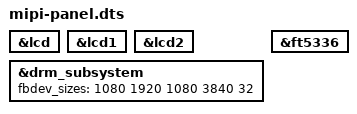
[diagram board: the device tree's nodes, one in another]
/dts-v1/;
/plugin/;

/ {
	fragment@0 {
		target = <&lcd>;

		__overlay__ {
			status = "okay";
		};
	};

	fragment@1 {
		target = <&lcd1>;

		__overlay__ {
			status = "okay";
		};
	};

	fragment@2 {
		target = <&lcd2>;

		__overlay__ {
			status = "okay";
		};
	};

	fragment@3 {
		target = <&drm_subsystem>;

		__overlay__ {
			fbdev_sizes = <1080 1920 1080 3840 32>;
		};
	};

	fragment@4 {
		target = <&ft5336>;

		__overlay__ {
			status = "okay";
		};
	};
};
